# MSPM0G321X register map
Vendor: Texas Instruments; File version: Revised: 2025-10-06 10:58:04
CPU: CM0 r0p1, little endian, MPU, no FPU, 3 interrupt priority bits
Registers are 32-bit, read-write, reset 0x0 unless marked. A register's access mark holds for its fields unless they carry their own. Offsets are from the block's base; [hi:lo] are bit positions; lines under a group give offsets from that group; {n}, {i} and the like mark numbered series; 'fields as' and 'values as' point back to an identical list.

## COMP0 — PERIPHERALREGION
Base 0x40008000
0x400 COMP0_FSUB_0 — Subscriber Port 0
  [3:0] CHANID — 0 = disconnected. 1-15 = connected to channelID = CHANID.
    0=UNCONNECTED (A value of 0 specifies that the event is not connected)
0x404 COMP0_FSUB_1 — Subscriber Port 1
  fields as COMP0_FSUB_0
0x444 COMP0_FPUB_1 — Publisher port 1
  fields as COMP0_FSUB_0
{0x800+0x18*i} COMP0_GPRCM[{i}] (i=0..0) group
  0x00 COMP0_PWREN — Power enable
    [0] ENABLE — Enable the power
      0=DISABLE (Disable Power); 1=ENABLE (Enable Power)
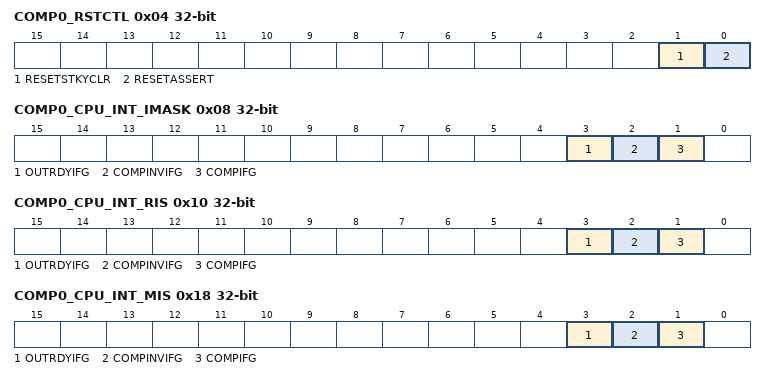
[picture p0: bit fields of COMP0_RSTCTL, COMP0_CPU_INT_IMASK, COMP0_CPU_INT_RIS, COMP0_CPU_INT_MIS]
  0x04 COMP0_RSTCTL wo — Reset Control
    [1] RESETSTKYCLR — Clear the RESETSTKY bit in the STAT register
      0=NOP (Writing 0 has no effect); 1=CLR (Clear reset sticky bit)
    [0] RESETASSERT — Assert reset to the peripheral
      0=NOP (Writing 0 has no effect); 1=ASSERT (Assert reset)
  0x08 COMP0_CLKCFG — Peripheral Clock Configuration Register
    [8] BLOCKASYNC — Async Clock Request is blocked from starting SYSOSC or forcing bus clock to 32MHz
      0=disable COMP to request SYSOSC; 1=enable COMP to request SYSOSC
  0x14 COMP0_GPRCM_STAT ro — Status Register
    [16] RESETSTKY — This bit indicates, if the peripheral was reset, since this bit was cleared by RESETSTKYCLR in the RSTCTL register
      0=NORES (The peripheral has not been reset since this bit was last cleared by RESETSTKYCLR in the RSTCTL register); 1=RESET (The peripheral was reset since the last bit clear)
{0x1020+0x2C*i} COMP0_CPU_INT[{i}] (i=0..0) group
  0x00 COMP0_CPU_INT_IIDX ro — Interrupt index
    [1:0] STAT — Interrupt index status
      0=NO_INTR (No pending interrupt); 2=COMPIFG (Comparator output interrupt); 3=COMPINVIFG (Comparator output inverted interrupt); 4=OUTRDYIFG (Comparator output ready interrupt)
  0x08 COMP0_CPU_INT_IMASK — Interrupt mask
    [all] fields
      0=CLR (Interrupt is masked out); 1=SET (Interrupt will request an interrupt service routine and corresponding bit in MIS will be set)
    [3] OUTRDYIFG — Masks OUTRDYIFG
    [2] COMPINVIFG — Masks COMPINVIFG
    [1] COMPIFG — Masks COMPIFG
  0x10 COMP0_CPU_INT_RIS ro — Raw interrupt status
    [all] fields
      0=CLR (No interrupt pending); 1=SET (Interrupt pending)
    [3] OUTRDYIFG — Raw interrupt status for comparator output ready interrupt flag. This bit is set when the comparator output is valid.
    [2] COMPINVIFG — Raw interrupt status for comparator output inverted interrupt flag. The IES bit defines the transition of the comparator output setting this bit.
    [1] COMPIFG — Raw interrupt status for comparator output interrupt flag. The IES bit defines the transition of the comparator output setting this bit.
  0x18 COMP0_CPU_INT_MIS ro — Masked interrupt status
    [3] OUTRDYIFG — Masked interrupt status for OUTRDYIFG
      0=CLR (OUTRDYIFG does not request an interrupt service routine); 1=SET (OUTRDYIFG requests an interrupt service routine)
    [2] COMPINVIFG — Masked interrupt status for COMPINVIFG
      0=CLR (COMPINVIFG does not request an interrupt service routine); 1=SET (COMPINVIFG requests an interrupt service routine)
    [1] COMPIFG — Masked interrupt status for COMPIFG
      0=CLR (COMPIFG does not request an interrupt service routine); 1=SET (COMPIFG requests an interrupt service routine)
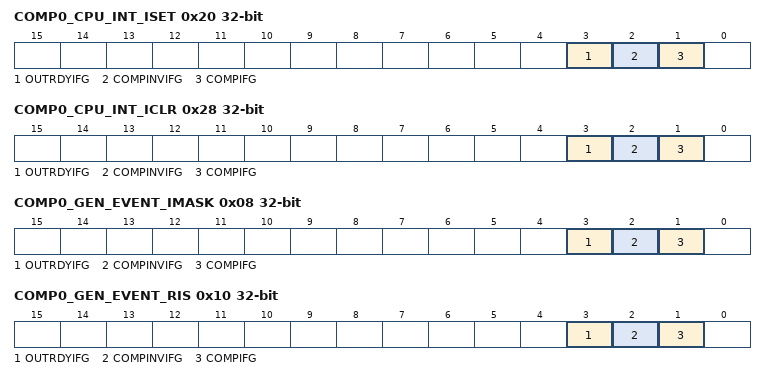
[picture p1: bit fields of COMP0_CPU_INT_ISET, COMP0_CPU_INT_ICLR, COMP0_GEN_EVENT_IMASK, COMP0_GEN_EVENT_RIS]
  0x20 COMP0_CPU_INT_ISET wo — Interrupt set
    [3] OUTRDYIFG — Sets OUTRDYIFG in RIS register
      0=NO_EFFECT (Writing a 0 has no effect); 1=SET (RIS bit corresponding to OUTRDYIFG is set)
    [2] COMPINVIFG — Sets COMPINVIFG in RIS register
      0=NO_EFFECT (Writing a 0 has no effect); 1=SET (RIS bit corresponding to COMPINVIFG is set)
    [1] COMPIFG — Sets COMPIFG in RIS register
      0=NO_EFFECT (Writing a 0 has no effect); 1=SET (RIS bit corresponding to COMPIFG is set)
  0x28 COMP0_CPU_INT_ICLR wo — Interrupt clear
    [3] OUTRDYIFG — Clears OUTRDYIFG in RIS register
      0=NO_EFFECT (Writing a 0 has no effect); 1=CLR (RIS bit corresponding to OUTRDYIFG is cleared)
    [2] COMPINVIFG — Clears COMPINVIFG in RIS register
      0=NO_EFFECT (Writing a 0 has no effect); 1=CLR (RIS bit corresponding to COMPINVIFG is cleared)
    [1] COMPIFG — Clears COMPIFG in RIS register
      0=NO_EFFECT (Writing a 0 has no effect); 1=CLR (RIS bit corresponding to COMPIFG is cleared)
{0x1050+0x2C*i} COMP0_GEN_EVENT[{i}] (i=0..0) group
  0x00 COMP0_GEN_EVENT_IIDX ro — Interrupt index
    fields as COMP0_CPU_INT[0].COMP0_CPU_INT_IIDX
  0x08 COMP0_GEN_EVENT_IMASK — Interrupt mask
    fields as COMP0_CPU_INT[0].COMP0_CPU_INT_IMASK
  0x10 COMP0_GEN_EVENT_RIS ro — Raw interrupt status
    fields as COMP0_CPU_INT[0].COMP0_CPU_INT_RIS
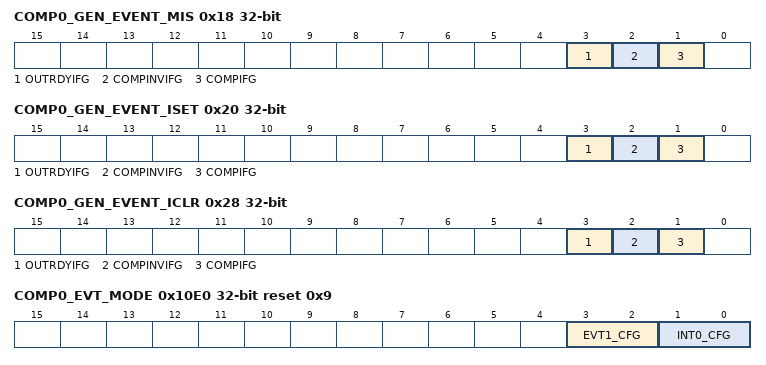
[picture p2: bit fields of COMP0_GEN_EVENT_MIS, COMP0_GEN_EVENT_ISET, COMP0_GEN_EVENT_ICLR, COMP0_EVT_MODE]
  0x18 COMP0_GEN_EVENT_MIS ro — Masked interrupt status
    fields as COMP0_CPU_INT[0].COMP0_CPU_INT_MIS
  0x20 COMP0_GEN_EVENT_ISET wo — Interrupt set
    fields as COMP0_CPU_INT[0].COMP0_CPU_INT_ISET
  0x28 COMP0_GEN_EVENT_ICLR wo — Interrupt clear
    fields as COMP0_CPU_INT[0].COMP0_CPU_INT_ICLR
0x10E0 COMP0_EVT_MODE reset 0x9 — Event Mode
  [3:2] EVT1_CFG ro — Event line mode select for event corresponding to GEN_EVENT
    0=DISABLE (The interrupt or event line is disabled.); 1=SOFTWARE (Event handled by software. Software must clear the associated RIS flag.); 2=HARDWARE (Event handled by hardware. The hardware (another module) clears automatically the associated RIS flag.)
  [1:0] INT0_CFG ro — Event line mode select for event corresponding to CPU_INT
    values as EVT1_CFG
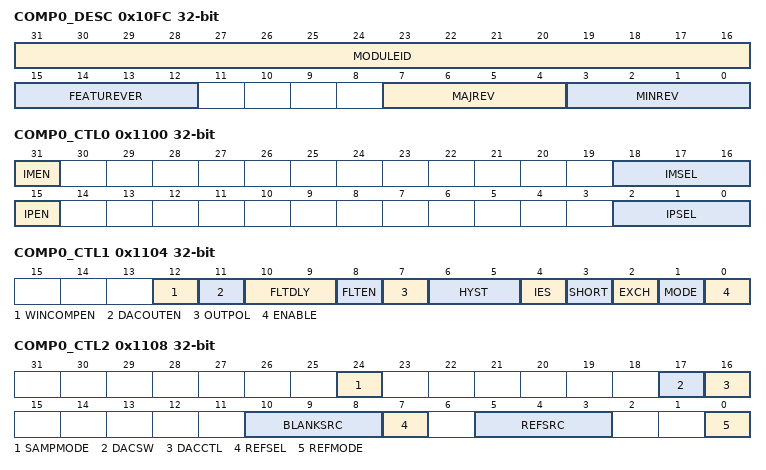
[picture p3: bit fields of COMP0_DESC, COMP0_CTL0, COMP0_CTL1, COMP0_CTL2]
0x10FC COMP0_DESC ro — Module Description
  [31:16] MODULEID — Module identification contains a unique peripheral identification number. The assignments are maintained in a central database for all of the platform modules to ensure uniqueness.
  [15:12] FEATUREVER — Feature Set for the module *instance*
  [7:4] MAJREV — Major rev of the IP
  [3:0] MINREV — Minor rev of the IP
0x1100 COMP0_CTL0 — Control 0
  [31] IMEN — Channel input enable for the negative terminal of the comparator.
    0=DISABLE (Selected analog input channel for negative terminal is disabled); 1=ENABLE (Selected analog input channel for negative terminal is enabled)
  [18:16] IMSEL — Channel input selected for the negative terminal of the comparator if IMEN is set to 1.
    {v}=CH_{v} (Channel {v} selected) (v=0..7)
  [15] IPEN — Channel input enable for the positive terminal of the comparator.
    0=DISABLE (Selected analog input channel for positive terminal is disabled); 1=ENABLE (Selected analog input channel for positive terminal is enabled)
  [2:0] IPSEL — Channel input selected for the positive terminal of the comparator if IPEN is set to 1.
    {v}=CH_{v} (Channel {v} selected) (v=0..7)
0x1104 COMP0_CTL1 — Control 1
  [12] WINCOMPEN — This bit enables window comparator operation of comparator.
    0=OFF (window comparator is disable); 1=ON (window comparator is enable)
  [11] DACOUTEN — This bit enables DAC8 output to be connected to the pin.
    0=DISABLE (Disable the DAC8 output connectivity to pin.); 1=ENABLE (Enable the DAC8 output connectivity to pin.)
  [10:9] FLTDLY — These bits select the comparator output filter delay. See the device-specific data sheet for specific values on comparator propagation delay for different filter delay settings.
    0=DLY_0 (Typical filter delay of 70 ns); 1=DLY_1 (Typical filter delay of 500 ns); 2=DLY_2 (Typical filter delay of 1200 ns); 3=DLY_3 (Typical filter delay of 2700 ns)
  [8] FLTEN — This bit enables the analog filter at comparator output.
    0=DISABLE (Comparator output filter is disabled); 1=ENABLE (Comparator output filter is enabled)
  [7] OUTPOL — This bit selects the comparator output polarity.
    0=NON_INV (Comparator output is non-inverted); 1=INV (Comparator output is inverted)
  [6:5] HYST — These bits select the hysteresis setting of the comparator.
    0=NO_HYS (No hysteresis); 1=LOW_HYS (Low hysteresis, typical 10mV); 2=MED_HYS (Medium hysteresis, typical 20mV); 3=HIGH_HYS (High hysteresis, typical 30mV)
  [4] IES — This bit selected the interrupt edge for COMPIFG and COMPINVIFG.
    0=RISING (Rising edge sets COMPIFG and falling edge sets COMPINVIFG); 1=FALLING (Falling edge sets COMPIFG and rising edge sets COMPINVIFG)
  [3] SHORT — This bit shorts the positive and negative input terminals of the comparator.
    0=NO_SHT (Comparator positive and negative input terminals are not shorted); 1=SHT (Comparator positive and negative input terminals are shorted)
  [2] EXCH — This bit exchanges the comparator inputs and inverts the comparator output.
    0=NO_EXC (Comparator inputs not exchanged and output not inverted); 1=EXC (Comparator inputs exchanged and output inverted)
  [1] MODE — This bit selects the comparator operating mode.
    0=FAST (Comparator is in fast mode); 1=ULP (Comparator is in ultra-low power mode)
  [0] ENABLE — This bit turns on the comparator. When the comparator is turned off it consumes no power.
    0=OFF (Comparator is off); 1=ON (Comparator is on)
0x1108 COMP0_CTL2 — Control 2
  [24] SAMPMODE — Enable sampled mode of comparator.
    0=DISABLE (Sampled mode disabled); 1=ENABLE (Sampled mode enabled)
  [17] DACSW — This bit selects between DACCODE0 and DACCODE1 to 8-bit DAC when DACCTL bit is 1.
    0=DACCODE0_SEL (DACCODE0 selected for 8-bit DAC); 1=DACCODE1_SEL (DACCODE1 selected for 8-bit DAC)
  [16] DACCTL — This bit determines if the comparator output or DACSW bit controls the selection between DACCODE0 and DACCODE1.
    0=COMPOUT_SEL (Comparator output controls selection between DACCODE0 and DACCODE1); 1=DACSW_SEL (DACSW bit controls selection between DACCODE0 and DACCODE1)
  [10:8] BLANKSRC — These bits select the blanking source for the comparator.
    0=DISABLE (Blanking source disabled); {v}=Select Blanking Source {v} (v=1..6)
  [7] REFSEL — This bit selects if the selected reference voltage is applied to positive or negative terminal of the comparator.
    0=POSITIVE (If EXCH bit is 0, the selected reference is applied to positive terminal. If EXCH bit is 1, the selected reference is applied to negative terminal.); 1=NEGATIVE (If EXCH bit is 0, the selected reference is applied to negative terminal. If EXCH bit is 1, the selected reference is applied to positive terminal.)
  [5:3] REFSRC — These bits select the reference source for the comparator.
    0=OFF (Reference voltage generator is disabled (local reference buffer as well as DAC).); 1=VDDA_DAC (VDDA selected as the reference source to DAC and DAC output applied as reference to comparator.); 2=VREF_DAC (VREF selected as reference to DAC and DAC output applied as reference to comparator.); 3=VREF (In devices where internal VREF is buffered and hookedup to extrernal VREF pin, VREF applied as reference to comparator. DAC is switched off.); 5=VDDA (VDDA is used as comparator reference.); 6=INTVREF_DAC (Internal reference selected as the reference source to DAC and DAC output applied as reference to comparator.); 7=INTVREF (Internal VREF is used as the source of comparator. Not all devices will have this option.)
  [0] REFMODE — This bit requests ULP_REF bandgap operation in fast mode(static) or low power mode (sampled). The local reference buffer and 8-bit DAC inside comparator module are also configured accordingly. Fast mode operation offers higher accuracy but consumes higher current. Low power operation consumes lower current but with relaxed reference voltage accuracy. Comparator requests for reference voltage from ULP_REF only when REFLVL > 0.
    0=STATIC (ULP_REF bandgap, local reference buffer and 8-bit DAC inside comparator operate in static mode.); 1=SAMPLED (ULP_REF bandgap, local reference buffer and 8-bit DAC inside comparator operate in sampled mode.)
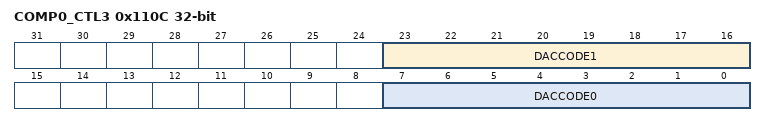
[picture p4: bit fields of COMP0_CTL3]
0x110C COMP0_CTL3 — Control 3
  [23:16] DACCODE1 — This is the second 8-bit DAC code. When the DAC code is 0x0 the DAC output will be selected reference voltage x 1/256 V. When the DAC code is 0xFF the DAC output will be selected reference voltage x 255/256 V.
  [7:0] DACCODE0 — This is the first 8-bit DAC code. When the DAC code is 0x0 the DAC output will be selected reference voltage x 1/256 V. When the DAC code is 0xFF the DAC output will be selected reference voltage x 255/256 V.
0x1120 COMP0_STAT ro — Status
  [0] OUT — This bit reflects the value of the comparator output. Writing to this bit has no effect on the comparator output.
    0=LOW (Comparator output is low); 1=HIGH (Comparator output is high)

## WUC — PERIPHERALREGION
Base 0x40424000
Registers as COMP0 (with COMP0 read as WUC), without COMP0_FPUB_1, COMP0_GPRCM[*], COMP0_CPU_INT[*], COMP0_GEN_EVENT[*], COMP0_EVT_MODE, COMP0_DESC, COMP0_CTL{n} (n=0..3), COMP0_STAT.

## COMP1 — PERIPHERALREGION
Base 0x4000A000
Registers as COMP0 (with COMP0 read as COMP1).
